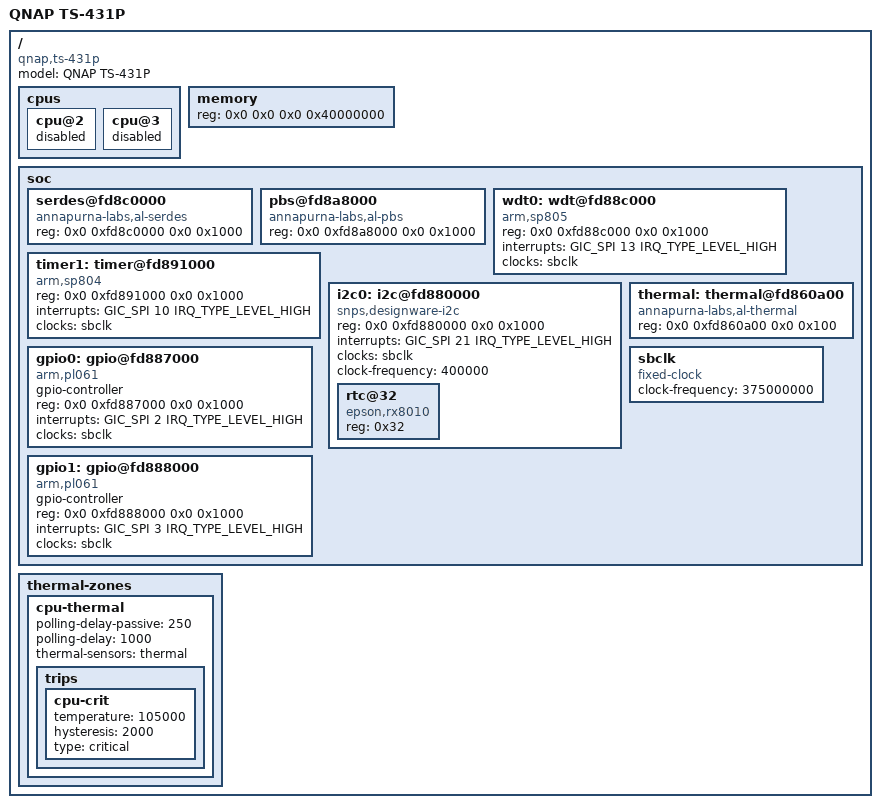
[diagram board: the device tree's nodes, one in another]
/*
 * Device Tree for QNAP TS-431P (Annapurna Labs Alpine AL-212)
 *
 * Based on alpine.dtsi (kernel mainline) with additions from
 * the QNAP stock DTB for serdes, watchdog, thermal, and I2C.
 *
 * PCIe uses pci-host-ecam-generic (from alpine.dtsi) for SATA.
 * Ethernet board params are in MAC scratch registers (set by U-Boot).
 * Only the serdes node is needed from DT for al_eth network driver.
 */

/dts-v1/;

#include "alpine.dtsi"

/ {
	model = "QNAP TS-431P";
	compatible = "qnap,ts-431p", "al,alpine";

	/* AL-212 is dual-core, disable cpu@2 and cpu@3 from alpine.dtsi */
	cpus {
		cpu@2 {
			status = "disabled";
		};
		cpu@3 {
			status = "disabled";
		};
	};

	memory {
		device_type = "memory";
		reg = <0x0 0x0 0x0 0x40000000>; /* 1 GB */
	};

	soc {
		/* SerDes — required by al_eth driver */
		serdes@fd8c0000 {
			compatible = "annapurna-labs,al-serdes";
			reg = <0x0 0xfd8c0000 0x0 0x1000>;
		};

		/* PBS registers */
		pbs@fd8a8000 {
			compatible = "annapurna-labs,al-pbs";
			reg = <0x0 0xfd8a8000 0x0 0x1000>;
		};

		/* Watchdog (sp805) — for systemd watchdog feeding */
		wdt0: wdt@fd88c000 {
			compatible = "arm,sp805", "arm,primecell";
			reg = <0x0 0xfd88c000 0x0 0x1000>;
			interrupts = <GIC_SPI 13 IRQ_TYPE_LEVEL_HIGH>;
			clocks = <&sbclk>;
			clock-names = "apb_pclk";
		};

		/* Timer (sp804) — needed for clock source */
		timer1: timer@fd891000 {
			compatible = "arm,sp804", "arm,primecell";
			reg = <0x0 0xfd891000 0x0 0x1000>;
			interrupts = <GIC_SPI 10 IRQ_TYPE_LEVEL_HIGH>;
			clocks = <&sbclk>;
			clock-names = "sbclk";
		};

		/* I2C — for RTC (Epson RX8010) and PIC controller */
		i2c0: i2c@fd880000 {
			#address-cells = <1>;
			#size-cells = <0>;
			compatible = "snps,designware-i2c";
			reg = <0x0 0xfd880000 0x0 0x1000>;
			interrupts = <GIC_SPI 21 IRQ_TYPE_LEVEL_HIGH>;
			clocks = <&sbclk>;
			clock-frequency = <400000>;

			rtc@32 {
				compatible = "epson,rx8010";
				reg = <0x32>;
			};
		};

		/* Thermal sensor */
		thermal: thermal@fd860a00 {
			compatible = "annapurna-labs,al-thermal";
			reg = <0x0 0xfd860a00 0x0 0x100>;
			#thermal-sensor-cells = <0>;
		};

		/* GPIO controllers */
		gpio0: gpio@fd887000 {
			#gpio-cells = <2>;
			compatible = "arm,pl061", "arm,primecell";
			gpio-controller;
			reg = <0x0 0xfd887000 0x0 0x1000>;
			interrupts = <GIC_SPI 2 IRQ_TYPE_LEVEL_HIGH>;
			clocks = <&sbclk>;
			clock-names = "apb_pclk";
		};

		gpio1: gpio@fd888000 {
			#gpio-cells = <2>;
			compatible = "arm,pl061", "arm,primecell";
			gpio-controller;
			reg = <0x0 0xfd888000 0x0 0x1000>;
			interrupts = <GIC_SPI 3 IRQ_TYPE_LEVEL_HIGH>;
			clocks = <&sbclk>;
			clock-names = "apb_pclk";
		};

		/* SB clock reference — needed by timers, watchdog, I2C */
		sbclk: sbclk {
			#clock-cells = <0>;
			compatible = "fixed-clock";
			clock-frequency = <375000000>; /* 375 MHz */
		};
	};

	thermal-zones {
		cpu-thermal {
			polling-delay-passive = <250>;
			polling-delay = <1000>;
			thermal-sensors = <&thermal>;

			trips {
				cpu-crit {
					temperature = <105000>;
					hysteresis = <2000>;
					type = "critical";
				};
			};
		};
	};
};
